VERSION ""

NS_ :

BS_:

BU_:

BO_ 2158739747 test: 8 Vector__XXX
	SG_ Speed : 0|16@1- (0.1,0) [0|99] "mph" Vector__XXX
	SG_ APPS : 16|16@1- (0.1,0) [-230|230] "" Vector__XXX

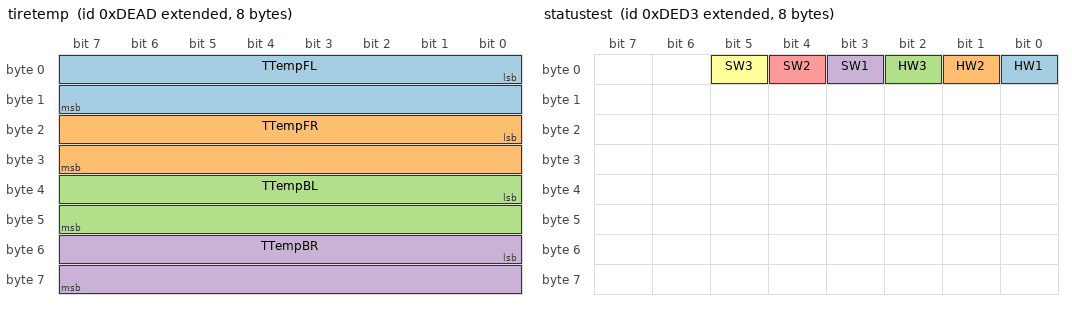
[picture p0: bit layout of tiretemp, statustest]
BO_ 2147540653 tiretemp: 8 Vector__XXX
	SG_ TTempFL : 0|16@1- (0.1,0) [0|99] "C" Vector__XXX
	SG_ TTempFR : 16|16@1- (0.1,0) [0|99] "C" Vector__XXX
	SG_ TTempBL : 32|16@1- (0.1,0) [0|99] "C" Vector__XXX
	SG_ TTempBR : 48|16@1- (0.1,0) [0|99] "C" Vector__XXX

BO_ 2147540691 statustest: 8 Vector__XXX
	SG_ HW1 : 0|1@1+ (1,0) [0|1] "" Vector__XXX
	SG_ HW2 : 1|1@1+ (1,0) [0|1] "" Vector__XXX
	SG_ HW3 : 2|1@1+ (1,0) [0|1] "" Vector__XXX
	SG_ SW1 : 3|1@1+ (1,0) [0|1] "" Vector__XXX
	SG_ SW2 : 4|1@1+ (1,0) [0|1] "" Vector__XXX
	SG_ SW3 : 5|1@1+ (1,0) [0|1] "" Vector__XXX

BO_ 2147540690 testagain: 8 Vector__XXX
	SG_ PackTemp : 0|16@1- (0.1, 0) [0|99] "C" Vector__XXX

BA_DEF_ SG_  "SPN" INT 0 524287;
BA_DEF_ BO_  "VFrameFormat" ENUM  "StandardCAN","ExtendedCAN","reserved","J1939PG";
BA_DEF_  "DatabaseVersion" STRING ;
BA_DEF_  "BusType" STRING ;
BA_DEF_  "ProtocolType" STRING ;
BA_DEF_  "DatabaseCompiler" STRING ;
BA_DEF_DEF_  "SPN" 0;
BA_DEF_DEF_  "VFrameFormat" "J1939PG";
BA_DEF_DEF_  "DatabaseVersion" "DEMO PLUS";
BA_DEF_DEF_  "BusType" "";
BA_DEF_DEF_  "ProtocolType" "";
BA_DEF_DEF_  "DatabaseCompiler" "";
BA_ "ProtocolType" "J1939";
BA_ "BusType" "CAN";
BA_ "DatabaseCompiler" "CSS ELECTRONICS (WWW.CSSELECTRONICS.COM)";
BA_ "DatabaseVersion" "1.0.0";
BA_ "SPN" SG_ 2158739747 WheelBasedVehicleSpeed 84;
